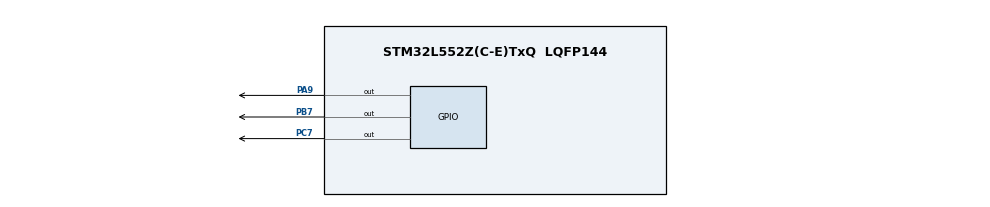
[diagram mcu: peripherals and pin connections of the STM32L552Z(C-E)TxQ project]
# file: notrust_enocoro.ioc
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Mcu.Family=STM32L5
Mcu.Name=STM32L552Z(C-E)TxQ
Mcu.Package=LQFP144
NVIC.PriorityGroup=NVIC_PRIORITYGROUP_3
PA9.Signal=GPIO_Output
PB7.Signal=GPIO_Output
PC7.Signal=GPIO_Output
ProjectManager.HeapSize=0x200
ProjectManager.StackSize=0x400
ProjectManager.TargetToolchain=STM32CubeIDE
RCC.HSE_VALUE=16000000
RCC.HSI48_VALUE=48000000
RCC.HSI_VALUE=16000000
RCC.LSE_VALUE=32768
RCC.MSI_VALUE=4000000
RCC.VCOOutputFreq_Value=32000000
board=custom

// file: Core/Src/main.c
/* USER CODE BEGIN Header */
/**
  ******************************************************************************
  * @file           : main.c
  * @brief          : Main program body
  ******************************************************************************
  * @attention
  *
  * Copyright (c) 2023 STMicroelectronics.
  * All rights reserved.
  *
  * This software is licensed under terms that can be found in the LICENSE file
  * in the root directory of this software component.
  * If no LICENSE file comes with this software, it is provided AS-IS.
  *
  ******************************************************************************
  */
/* USER CODE END Header */
#include "main.h"

/* USER CODE BEGIN Includes */
#include "util.h"
#include "enocoro.h"
#include <time.h>
/* USER CODE END Includes */

void SystemClock_Config(void);
static void MX_GPIO_Init(void);

int main(void)
{
  /* USER CODE BEGIN 1 */
	  CoreDebug->DEMCR |= CoreDebug_DEMCR_TRCENA_Msk;
	  DWT->CYCCNT = 0;
	  DWT->CTRL  |= 1;
  /* USER CODE END 1 */

  /* MCU Configuration--------------------------------------------------------*/

  /* Reset of all peripherals, Initializes the Flash interface and the Systick. */
  HAL_Init();

  /* Configure the system clock */
  SystemClock_Config();

  /* Initialize all configured peripherals */
  MX_GPIO_Init();

  /* Infinite loop */
  while (1)
  {

    /* USER CODE BEGIN 3 */
		HAL_GPIO_TogglePin(GPIOA, GPIO_PIN_9);

		#define STRING_LENGTH 64

		// NUM_ENC = STRING_LENGTH / 16
		#define NUM_ENC 4

		uint8_t plain[64] = { (uint8_t) 0x6b, (uint8_t) 0xc1, (uint8_t) 0xbe, (uint8_t) 0xe2,
							  (uint8_t) 0x2e, (uint8_t) 0x40, (uint8_t) 0x9f, (uint8_t) 0x96,
							  (uint8_t) 0xe9, (uint8_t) 0x3d, (uint8_t) 0x7e, (uint8_t) 0x11,
							  (uint8_t) 0x73, (uint8_t) 0x93, (uint8_t) 0x17, (uint8_t) 0x2a,
							  (uint8_t) 0xae, (uint8_t) 0x2d, (uint8_t) 0x8a, (uint8_t) 0x57,
							  (uint8_t) 0x1e, (uint8_t) 0x03, (uint8_t) 0xac, (uint8_t) 0x9c,
							  (uint8_t) 0x9e, (uint8_t) 0xb7, (uint8_t) 0x6f, (uint8_t) 0xac,
							  (uint8_t) 0x45, (uint8_t) 0xaf, (uint8_t) 0x8e, (uint8_t) 0x51,
							  (uint8_t) 0x30, (uint8_t) 0xc8, (uint8_t) 0x1c, (uint8_t) 0x46,
							  (uint8_t) 0xa3, (uint8_t) 0x5c, (uint8_t) 0xe4, (uint8_t) 0x11,
							  (uint8_t) 0xe5, (uint8_t) 0xfb, (uint8_t) 0xc1, (uint8_t) 0x19,
							  (uint8_t) 0x1a, (uint8_t) 0x0a, (uint8_t) 0x52, (uint8_t) 0xef,
							  (uint8_t) 0xf6, (uint8_t) 0x9f, (uint8_t) 0x24, (uint8_t) 0x45,
							  (uint8_t) 0xdf, (uint8_t) 0x4f, (uint8_t) 0x9b, (uint8_t) 0x17,
							  (uint8_t) 0xad, (uint8_t) 0x2b, (uint8_t) 0x41, (uint8_t) 0x7b,
							  (uint8_t) 0xe6, (uint8_t) 0x6c, (uint8_t) 0x37, (uint8_t) 0x10
						    };
		uint8_t key[16] = { (uint8_t) 0x5d, (uint8_t) 0x6e, (uint8_t) 0x7f, (uint8_t) 0x80,
							(uint8_t) 0x91, (uint8_t) 0xa2, (uint8_t) 0xb3, (uint8_t) 0xc4,
							(uint8_t) 0xd5, (uint8_t) 0xe6, (uint8_t) 0xf7, (uint8_t) 0x08,
							(uint8_t) 0x19, (uint8_t) 0x2a, (uint8_t) 0x3b, (uint8_t) 0x4c
						  };
		uint8_t iv[16] = { (uint8_t) 0x01, (uint8_t) 0x23, (uint8_t) 0x45, (uint8_t) 0x67,
						   (uint8_t) 0x89, (uint8_t) 0xab, (uint8_t) 0xcd, (uint8_t) 0xef,
						   (uint8_t) 0x01, (uint8_t) 0x23, (uint8_t) 0x45, (uint8_t) 0x67,
						   (uint8_t) 0x89, (uint8_t) 0xab, (uint8_t) 0xcd, (uint8_t) 0xef
						 };

		print_hex(plain, STRING_LENGTH);

		uint32_t key_cycle_count = DWT->CYCCNT;

		uint8_t i;

		/* clear ket-stream area */
		uint8_t keystream[STRING_LENGTH] = {0};

		/* define context-struct */
		ENOCORO_Ctx ctx;
		memset(&ctx, 0, sizeof(ENOCORO_Ctx));

		/* setup init */
		ENOCORO_init(&ctx, key, ENOCORO128_KEY_BYTE_SIZE, iv, ENOCORO_IV_BYTE_SIZE);

		/* output randum value */
		ENOCORO_keystream(&ctx, keystream, STRING_LENGTH);

		uint32_t enc_start_cycle_count = DWT->CYCCNT;
		/* encrypt */
		for (i = 0; i < STRING_LENGTH; i++)
			plain[i] ^= keystream[i];
		uint32_t enc_end_cycle_count = DWT->CYCCNT;

		print_hex(plain, STRING_LENGTH);

		uint32_t dec_start_cycle_count = DWT->CYCCNT;
		/* decrypt */
		for (i = 0; i < STRING_LENGTH; i++)
			plain[i] ^= keystream[i];
		uint32_t dec_end_cycle_count = DWT->CYCCNT;

		print_hex(keystream, STRING_LENGTH);
		print_hex(plain, STRING_LENGTH);

		uint32_t key_cycles = enc_start_cycle_count - key_cycle_count;
	    uint32_t enc_total_cycles = enc_end_cycle_count - enc_start_cycle_count;
	    uint32_t dec_total_cycles = dec_end_cycle_count - dec_start_cycle_count;

	    printf("Key cycles: %u\n", key_cycles);
	    printf("\nEnc start cycles: %u\n", enc_start_cycle_count);
	    printf("Enc end cycles: %u\n", enc_end_cycle_count);
	    printf("Enc total cycles: %u\n", enc_total_cycles);
	    printf("\nDec start cycles: %u\n", dec_start_cycle_count);
	    printf("Dec end cycles: %u\n", dec_end_cycle_count);
	    printf("Dec total cycles: %u\n", dec_total_cycles);
	    printf("\nKey + Enc: %u\n", key_cycles + enc_total_cycles);
	    printf("Key + Dec: %u\n", key_cycles + dec_total_cycles);

	    HAL_GPIO_TogglePin(GPIOB, GPIO_PIN_7);

	    break;
  }
  /* USER CODE END 3 */
}

void SystemClock_Config(void)
{
  RCC_OscInitTypeDef RCC_OscInitStruct = {0};
  RCC_ClkInitTypeDef RCC_ClkInitStruct = {0};

  /** Configure the main internal regulator output voltage
  */
  if (HAL_PWREx_ControlVoltageScaling(PWR_REGULATOR_VOLTAGE_SCALE2) != HAL_OK)
  {
    Error_Handler();
  }

  /** Initializes the RCC Oscillators according to the specified parameters
  * in the RCC_OscInitTypeDef structure.
  */
  RCC_OscInitStruct.OscillatorType = RCC_OSCILLATORTYPE_MSI;
  RCC_OscInitStruct.MSIState = RCC_MSI_ON;
  RCC_OscInitStruct.MSICalibrationValue = RCC_MSICALIBRATION_DEFAULT;
  RCC_OscInitStruct.MSIClockRange = RCC_MSIRANGE_6;
  RCC_OscInitStruct.PLL.PLLState = RCC_PLL_NONE;
  if (HAL_RCC_OscConfig(&RCC_OscInitStruct) != HAL_OK)
  {
    Error_Handler();
  }

  /** Initializes the CPU, AHB and APB buses clocks
  */
  RCC_ClkInitStruct.ClockType = RCC_CLOCKTYPE_HCLK|RCC_CLOCKTYPE_SYSCLK
                              |RCC_CLOCKTYPE_PCLK1|RCC_CLOCKTYPE_PCLK2;
  RCC_ClkInitStruct.SYSCLKSource = RCC_SYSCLKSOURCE_MSI;
  RCC_ClkInitStruct.AHBCLKDivider = RCC_SYSCLK_DIV1;
  RCC_ClkInitStruct.APB1CLKDivider = RCC_HCLK_DIV1;
  RCC_ClkInitStruct.APB2CLKDivider = RCC_HCLK_DIV1;

  if (HAL_RCC_ClockConfig(&RCC_ClkInitStruct, FLASH_LATENCY_0) != HAL_OK)
  {
    Error_Handler();
  }
}

static void MX_GPIO_Init(void)
{
  GPIO_InitTypeDef GPIO_InitStruct = {0};

  /* GPIO Ports Clock Enable */
  __HAL_RCC_GPIOC_CLK_ENABLE();
  __HAL_RCC_GPIOA_CLK_ENABLE();
  __HAL_RCC_GPIOB_CLK_ENABLE();

  /*Configure GPIO pin Output Level */
  HAL_GPIO_WritePin(GPIOC, GPIO_PIN_7, GPIO_PIN_RESET);

  /*Configure GPIO pin Output Level */
  HAL_GPIO_WritePin(GPIOA, GPIO_PIN_9, GPIO_PIN_RESET);

  /*Configure GPIO pin Output Level */
  HAL_GPIO_WritePin(GPIOB, GPIO_PIN_7, GPIO_PIN_RESET);

  /*Configure GPIO pin : PC7 */
  GPIO_InitStruct.Pin = GPIO_PIN_7;
  GPIO_InitStruct.Mode = GPIO_MODE_OUTPUT_PP;
  GPIO_InitStruct.Pull = GPIO_NOPULL;
  GPIO_InitStruct.Speed = GPIO_SPEED_FREQ_LOW;
  HAL_GPIO_Init(GPIOC, &GPIO_InitStruct);

  /*Configure GPIO pin : PA9 */
  GPIO_InitStruct.Pin = GPIO_PIN_9;
  GPIO_InitStruct.Mode = GPIO_MODE_OUTPUT_PP;
  GPIO_InitStruct.Pull = GPIO_NOPULL;
  GPIO_InitStruct.Speed = GPIO_SPEED_FREQ_LOW;
  HAL_GPIO_Init(GPIOA, &GPIO_InitStruct);

  /*Configure GPIO pin : PB7 */
  GPIO_InitStruct.Pin = GPIO_PIN_7;
  GPIO_InitStruct.Mode = GPIO_MODE_OUTPUT_PP;
  GPIO_InitStruct.Pull = GPIO_NOPULL;
  GPIO_InitStruct.Speed = GPIO_SPEED_FREQ_LOW;
  HAL_GPIO_Init(GPIOB, &GPIO_InitStruct);

}

/* USER CODE BEGIN 4 */
int __io_putchar(int ch)
{
	return ITM_SendChar(ch);
}
/* USER CODE END 4 */

void Error_Handler(void)
{
  __disable_irq();
  while (1)
  {
  }
}
